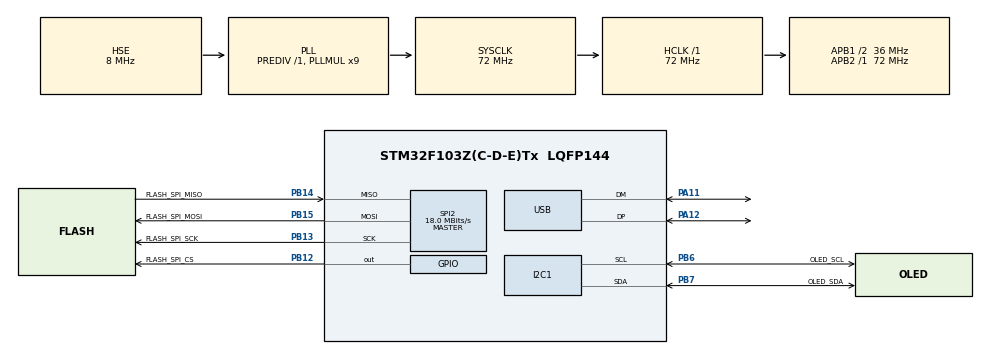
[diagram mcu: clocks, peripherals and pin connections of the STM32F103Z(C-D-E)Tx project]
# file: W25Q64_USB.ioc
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I2C1.I2C_Mode=I2C_Fast
Mcu.Family=STM32F1
Mcu.Name=STM32F103Z(C-D-E)Tx
Mcu.Package=LQFP144
NVIC.PriorityGroup=NVIC_PRIORITYGROUP_4
NVIC.USB_LP_CAN1_RX0_IRQn=true\:0\:0\:false\:false\:true\:false\:true
OSC_IN.Mode=HSE-External-Oscillator
OSC_IN.Signal=RCC_OSC_IN
OSC_OUT.Mode=HSE-External-Oscillator
OSC_OUT.Signal=RCC_OSC_OUT
PA11.Mode=Device
PA11.Signal=USB_DM
PA12.Mode=Device
PA12.Signal=USB_DP
PA13.Mode=Serial_Wire
PA13.Signal=SYS_JTMS-SWDIO
PA14.Mode=Serial_Wire
PA14.Signal=SYS_JTCK-SWCLK
PB12.GPIO_Label=FLASH_SPI_CS
PB12.GPIO_Speed=GPIO_SPEED_FREQ_LOW
PB12.Signal=GPIO_Output
PB13.GPIO_Label=FLASH_SPI_SCK
PB13.Mode=Full_Duplex_Master
PB13.Signal=SPI2_SCK
PB14.GPIO_Label=FLASH_SPI_MISO
PB14.Mode=Full_Duplex_Master
PB14.Signal=SPI2_MISO
PB15.GPIO_Label=FLASH_SPI_MOSI
PB15.Mode=Full_Duplex_Master
PB15.Signal=SPI2_MOSI
PB6.GPIO_Label=OLED_SCL
PB6.Mode=I2C
PB6.Signal=I2C1_SCL
PB7.GPIO_Label=OLED_SDA
PB7.Mode=I2C
PB7.Signal=I2C1_SDA
ProjectManager.HeapSize=0x200
ProjectManager.StackSize=0x400
ProjectManager.TargetToolchain=STM32CubeIDE
RCC.AHBFreq_Value=72000000
RCC.APB1CLKDivider=RCC_HCLK_DIV2
RCC.APB1Freq_Value=36000000
RCC.APB1TimFreq_Value=72000000
RCC.APB2Freq_Value=72000000
RCC.APB2TimFreq_Value=72000000
RCC.HCLKFreq_Value=72000000
RCC.PLLMUL=RCC_PLL_MUL9
RCC.PLLSourceVirtual=RCC_PLLSOURCE_HSE
RCC.SYSCLKFreq_VALUE=72000000
RCC.SYSCLKSource=RCC_SYSCLKSOURCE_PLLCLK
RCC.USBFreq_Value=48000000
RCC.USBPrescaler=RCC_USBCLKSOURCE_PLL_DIV1_5
SPI2.CalculateBaudRate=18.0 MBits/s
SPI2.Direction=SPI_DIRECTION_2LINES
SPI2.Mode=SPI_MODE_MASTER
SPI2.VirtualType=VM_MASTER
USB_DEVICE.CLASS_NAME_FS=MSC
USB_DEVICE.MANUFACTURER_STRING=YAHBOOM
USB_DEVICE.MSC_MEDIA_PACKET=4096
USB_DEVICE.PID_MSC_FS=22233
USB_DEVICE.PRODUCT_STRING_MSC_FS=W25Q64USB
USB_DEVICE.VID=1155
USB_DEVICE.VirtualMode=Msc
USB_DEVICE.VirtualModeFS=Msc_FS
VP_USB_DEVICE_VS_USB_DEVICE_MSC_FS.Mode=MSC_FS
board=custom

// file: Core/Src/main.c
/* USER CODE BEGIN Header */
/**
  ******************************************************************************
  * @file           : main.c
  * @brief          : Main program body
  ******************************************************************************
  * @attention
  *
  * <h2><center>&copy; Copyright (c) 2023 STMicroelectronics.
  * All rights reserved.</center></h2>
  *
  * This software component is licensed by ST under BSD 3-Clause license,
  * the "License"; You may not use this file except in compliance with the
  * License. You may obtain a copy of the License at:
  *                        opensource.org/licenses/BSD-3-Clause
  *
  ******************************************************************************
  */
/* USER CODE END Header */
#include "main.h"
#include "i2c.h"
#include "spi.h"
#include "usb_device.h"
#include "gpio.h"

/* USER CODE BEGIN Includes */
#include "bsp.h"
/* USER CODE END Includes */

void SystemClock_Config(void);

int main(void)
{

  /* MCU Configuration--------------------------------------------------------*/

  /* Reset of all peripherals, Initializes the Flash interface and the Systick. */
  HAL_Init();

  /* Configure the system clock */
  SystemClock_Config();

  /* USER CODE BEGIN SysInit */
  USB_Init();//防止烧完程序后需要插拔usb Prevent the need to plug and unplug the USB after burning the program
  /* USER CODE END SysInit */

  /* Initialize all configured peripherals */
  MX_GPIO_Init();
  MX_I2C1_Init();
  MX_SPI2_Init();
  MX_USB_DEVICE_Init();
  /* USER CODE BEGIN 2 */
  BSP_Init();
  /* USER CODE END 2 */

  /* Infinite loop */
  while (1)
  {

    /* USER CODE BEGIN 3 */
	  BSP_Loop();
  }
  /* USER CODE END 3 */
}

void SystemClock_Config(void)
{
  RCC_OscInitTypeDef RCC_OscInitStruct = {0};
  RCC_ClkInitTypeDef RCC_ClkInitStruct = {0};
  RCC_PeriphCLKInitTypeDef PeriphClkInit = {0};

  /** Initializes the RCC Oscillators according to the specified parameters
  * in the RCC_OscInitTypeDef structure.
  */
  RCC_OscInitStruct.OscillatorType = RCC_OSCILLATORTYPE_HSE;
  RCC_OscInitStruct.HSEState = RCC_HSE_ON;
  RCC_OscInitStruct.HSEPredivValue = RCC_HSE_PREDIV_DIV1;
  RCC_OscInitStruct.HSIState = RCC_HSI_ON;
  RCC_OscInitStruct.PLL.PLLState = RCC_PLL_ON;
  RCC_OscInitStruct.PLL.PLLSource = RCC_PLLSOURCE_HSE;
  RCC_OscInitStruct.PLL.PLLMUL = RCC_PLL_MUL9;
  if (HAL_RCC_OscConfig(&RCC_OscInitStruct) != HAL_OK)
  {
    Error_Handler();
  }
  /** Initializes the CPU, AHB and APB buses clocks
  */
  RCC_ClkInitStruct.ClockType = RCC_CLOCKTYPE_HCLK|RCC_CLOCKTYPE_SYSCLK
                              |RCC_CLOCKTYPE_PCLK1|RCC_CLOCKTYPE_PCLK2;
  RCC_ClkInitStruct.SYSCLKSource = RCC_SYSCLKSOURCE_PLLCLK;
  RCC_ClkInitStruct.AHBCLKDivider = RCC_SYSCLK_DIV1;
  RCC_ClkInitStruct.APB1CLKDivider = RCC_HCLK_DIV2;
  RCC_ClkInitStruct.APB2CLKDivider = RCC_HCLK_DIV1;

  if (HAL_RCC_ClockConfig(&RCC_ClkInitStruct, FLASH_LATENCY_2) != HAL_OK)
  {
    Error_Handler();
  }
  PeriphClkInit.PeriphClockSelection = RCC_PERIPHCLK_USB;
  PeriphClkInit.UsbClockSelection = RCC_USBCLKSOURCE_PLL_DIV1_5;
  if (HAL_RCCEx_PeriphCLKConfig(&PeriphClkInit) != HAL_OK)
  {
    Error_Handler();
  }
}

void Error_Handler(void)
{
  __disable_irq();
  while (1)
  {
  }
}

/************************ (C) COPYRIGHT STMicroelectronics *****END OF FILE****/
